VERSION ""

NS_ :

BS_:

BU_:

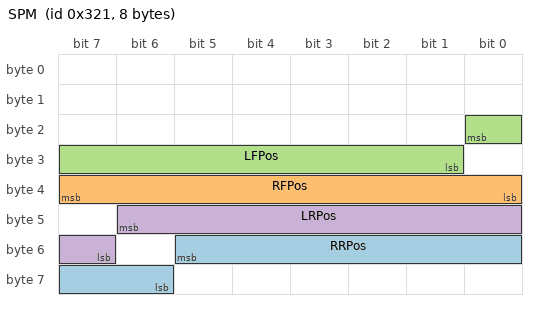
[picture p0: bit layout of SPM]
BO_ 801 SPM: 8 Vector__XXX
	SG_ RRPos : 53|8@0- (-1.4147,53.307) [0|0] "mm" Vector__XXX
	SG_ RFPos : 39|8@0- (-1.7052,77.6) [0|0] "mm" Vector__XXX
	SG_ LFPos : 16|8@0- (-1.7052,77.6) [0|0] "mm" Vector__XXX
	SG_ LRPos : 46|8@0- (-1.4147,53.307) [0|0] "mm" Vector__XXX

BO_ 417 Throttle: 7 Vector__XXX
	SG_ TPS : 55|8@0+ (0.3921568627,0) [0|100] "%" Vector__XXX

BO_ 501 Trans: 8 Vector__XXX
	SG_ Clutch : 63|8@0+ (0.3921568627,0) [0|100] "%" Vector__XXX
	SG_ Gear : 3|4@0+ (1,0) [0|14] "" Vector__XXX

BO_ 201 ECMEngineStatus: 8 Vector__XXX
	SG_ EngineTPS : 39|8@0+ (0.3921568627,0) [0|100] "%" Vector__XXX
	SG_ EngineRPM : 15|16@0+ (0.25,0) [0|0] "RPM" Vector__XXX

BO_ 485 PSCMSteeringAngle: 8 Vector__XXX
	SG_ SteeringWheelAngle : 15|16@0- (0.0625,0) [-2047|2047] "deg" Vector__XXX

CM_ BO_ 801 "Suspension Control Module";
CM_ SG_ 801 RRPos "Right Rear Position Sensor";
CM_ SG_ 801 RFPos "Left Rear Position Sensor";
CM_ SG_ 801 LFPos "Left Front Position Sensor";
CM_ SG_ 801 LRPos "Right Front Position Sensor";
CM_ BO_ 417 "Throttle Pedal Position";
CM_ BO_ 501 "Transmission Input";
CM_ SG_ 351 Clutch "Clutch Pedal Position";
CM_ SG_ 501 Gear "Gear Selector Position D=N E=R";
CM_ BO_ 201 "K20 ECM";
CM_ BO_ 485 "PSCM";
BA_DEF_ BO_  "VFrameFormat" ENUM  "StandardCAN","ExtendedCAN","reserved","J1939PG";
BA_DEF_  "DatabaseVersion" STRING ;
BA_DEF_  "BusType" STRING ;
BA_DEF_  "ProtocolType" STRING ;
BA_DEF_  "DatabaseCompiler" STRING ;
BA_DEF_DEF_  "VFrameFormat" "J1939PG";
BA_DEF_DEF_  "DatabaseVersion" "DEMO PLUS";
BA_DEF_DEF_  "BusType" "";
BA_DEF_DEF_  "ProtocolType" "";
BA_DEF_DEF_  "DatabaseCompiler" "";
BA_ "ProtocolType" "J1939";
BA_ "BusType" "CAN";
BA_ "DatabaseCompiler" "CSS ELECTRONICS (WWW.CSSELECTRONICS.COM)";
BA_ "DatabaseVersion" "1.0.0";
